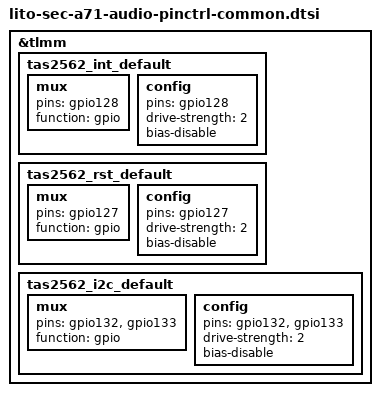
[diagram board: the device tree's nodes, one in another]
/* Copyright (c) 2019, The Linux Foundation. All rights reserved.
 *
 * This program is free software; you can redistribute it and/or modify
 * it under the terms of the GNU General Public License version 2 and
 * only version 2 as published by the Free Software Foundation.
 *
 * This program is distributed in the hope that it will be useful,
 * but WITHOUT ANY WARRANTY; without even the implied warranty of
 * MERCHANTABILITY or FITNESS FOR A PARTICULAR PURPOSE.  See the
 * GNU General Public License for more details.
 */

&tlmm {
	tas2562_int_default: tas2562_int_default {
		mux {
			pins = "gpio128";
			function = "gpio";
		};
		config {
			pins = "gpio128";
			drive-strength = <2>; /* 2 MA */
			bias-disable; /* No PULL */
		};
	};

	tas2562_rst_default: tas2562_rst_default {
		mux {
			pins = "gpio127";
			function = "gpio";
		};
		config {
			pins = "gpio127";
			drive-strength = <2>; /* 2 MA */
			bias-disable; /* No PULL */
		};
	};

	tas2562_i2c_default: tas2562_i2c_default {
		mux {
			pins = "gpio132", "gpio133";
			function = "gpio";
		};
			config {
			pins = "gpio132", "gpio133";
			drive-strength = <2>;	/* 2 mA */
			bias-disable;			/* NO PULL */
		};
	};
};
